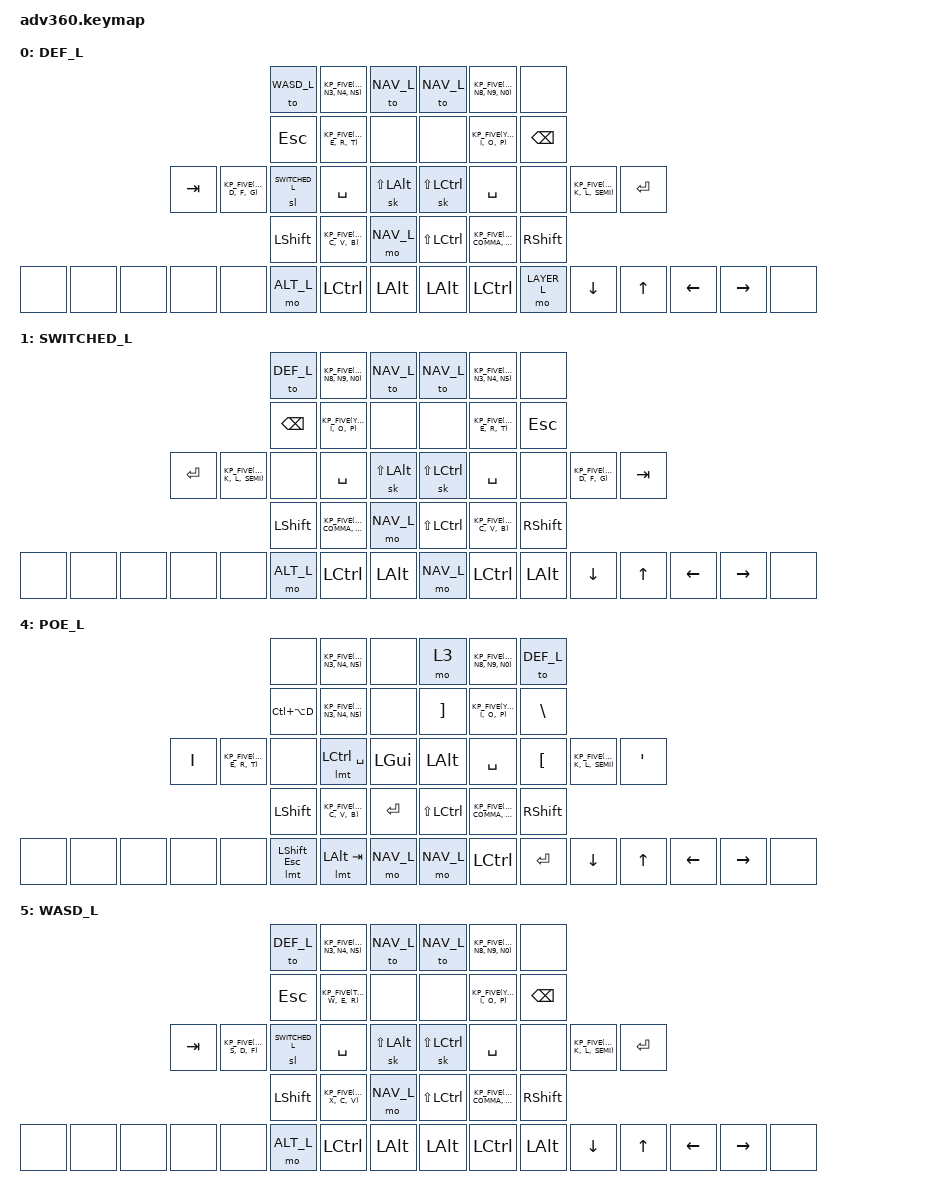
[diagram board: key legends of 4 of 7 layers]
#include <behaviors.dtsi>
#include <dt-bindings/zmk/keys.h>
#include <dt-bindings/zmk/bt.h>
#include <dt-bindings/zmk/rgb.h>
#include <dt-bindings/zmk/backlight.h>

#define TAPPING_TERM 210
#define SHIFT_TAP    170
#define QUICK_TAP    105

#define DEF_L      0
#define SWITCHED_L 1
#define NAV_L      2
#define ALT_L      3
#define POE_L      4
#define WASD_L     5
#define LAYER_L    6 

#define HRML(k1,k2,k3,k4) &lmt LCTRL k1  &lmt LALT k2  &lmt LGUI k3  &lst LSHFT k4
#define HRMR(k1,k2,k3,k4) &rst RSHFT k1  &rmt RGUI k2  &rmt RALT k3  &rmt RCTRL k4
#define KP_FIVE(k1,k2,k3,k4,k5) &kp k1  &kp k2  &kp k3  &kp k4  &kp k5

#define L_SHIFT 46
#define R_SHIFT 59
#define L_KEYS /*1*/0 1 2 3 4 5 6 /*2*/14 15 16 17 18 19 20 /*3*/28 29 30 31 32 33 34 35 36 /*4*/46 47 48 49 50 51 52 /*5*/60 61 62 63 64 65 66 67
#define R_KEYS /*1*/7 8 9 10 11 12 13 /*2*/21 22 23 24 25 26 27 /*3*/37 38 39 40 41 42 43 44 45 /*4*/53 54 55 56 57 58 59 /*6*/68 69 70 71 72 73 74 75

#define HOLD_TAP(name, tap_flavor, tap_term, ...) \
    name: name##_hold_tap {                       \
        label           = #name;                  \
        flavor          = #tap_flavor;            \
        compatible      = "zmk,behavior-hold-tap";\
        tapping-term-ms = <tap_term>;             \
        quick-tap-ms    = <QUICK_TAP>;            \
        #binding-cells  = <2>;                    \
        bindings        = <&kp>, <&kp>;           \
        __VA_ARGS__                               \
    };

#define LAYER_TAP(name, tap_flavor, tap_term, ...)\
    name: name##_layer_tap {                       \
        label           = #name;                  \
        flavor          = #tap_flavor;            \
        compatible      = "zmk,behavior-hold-tap";\
        tapping-term-ms = <tap_term>;             \
        quick-tap-ms    = <QUICK_TAP>;            \
        #binding-cells  = <2>;                    \
        bindings        = <&mo>, <&kp>;           \
        __VA_ARGS__                               \
    };

#define SEQUENCE_MACRO(name, keys)         \
    name: name##_macro {                   \
        label = #name;                     \
        compatible = "zmk,behavior-macro"; \
        wait-ms = <1>;                     \
        tap-ms = <1>;                      \
        #binding-cells = <0>;              \
        bindings = <keys>;                 \
    };

&sk {
    release-after-ms = <2000>;
    quick-release;
};

&mt {
  retro-tap;
};


/ {

  behaviors {
    #include "macros.dtsi"
    // Positional hold-tap for non-Shift modifiers
    HOLD_TAP(lmt, tap-preferred, TAPPING_TERM, hold-trigger-key-positions = <L_SHIFT R_KEYS>;)
    HOLD_TAP(rmt, tap-preferred, TAPPING_TERM, hold-trigger-key-positions = <R_SHIFT L_KEYS>;)
    // Positional hold-tap for Shift
    HOLD_TAP(lst, balanced, SHIFT_TAP, hold-trigger-key-positions = <R_KEYS>;)
    HOLD_TAP(rst, balanced, SHIFT_TAP, hold-trigger-key-positions = <L_KEYS>;)
    // Positional layer-tap
    LAYER_TAP(llt, tap-preferred, TAPPING_TERM, hold-trigger-key-positions = <L_SHIFT R_KEYS>;)
    LAYER_TAP(rlt, tap-preferred, TAPPING_TERM, hold-trigger-key-positions = <R_SHIFT L_KEYS>;)
  };

  macros {
    SEQUENCE_MACRO(terminal_next, &kp LS(LC(T)) &kp LS(LC(J)))
    SEQUENCE_MACRO(terminal_prev, &kp LS(LC(T)) &kp LS(LC(K)))
  };

  keymap {
    compatible = "zmk,keymap";

    DEF_L {
      bindings = <
        &to WASD_L KP_FIVE(N1, N2, N3, N4, N5)    &to NAV_L                                                                                         &to NAV_L     KP_FIVE(N6, N7, N8, N9, N0)                       &none
        &kp ESC    KP_FIVE(Q,  W,  E,  R,  T)     &none                                                                                             &none         KP_FIVE(Y,  U,  I,  O,  P)                        &kp BSPC
        &kp TAB    KP_FIVE(A,  S,  D,  F,  G)     &sl SWITCHED_L                      &kp SPACE &sk LS(LALT)  &sk LS(LCTRL)  &kp SPACE              &none         KP_FIVE(H,  J,  K,  L,  SEMI)                     &kp ENTER
        &kp LSHFT  KP_FIVE(Z,  X,  C,  V,  B)                                                      &mo NAV_L  &kp LS(LCTRL)                                       KP_FIVE(N,  M, COMMA, DOT, FSLH)                  &kp RSHFT
        &none &none &none &none &none                                         &mo ALT_L  &kp LCTRL  &kp LALT  &kp LALT &kp LCTRL &mo LAYER_L                            &kp DOWN &kp UP  &kp LEFT &kp RIGHT  &none
      >;
    };
    SWITCHED_L {
      bindings = <
        &to DEF_L  KP_FIVE(N6, N7, N8, N9, N0)    &to NAV_L                                                                                         &to NAV_L     KP_FIVE(N1, N2, N3, N4, N5)                       &none
        &kp BSPC   KP_FIVE(Y,  U,  I,  O,  P)     &none                                                                                             &none         KP_FIVE(Q,  W,  E,  R,  T)                        &kp ESC
        &kp ENTER  KP_FIVE(H,  J,  K,  L,  SEMI)  &none                               &kp SPACE &sk LS(LALT)  &sk LS(LCTRL)  &kp SPACE              &none         KP_FIVE(A,  S,  D,  F,  G)                     &kp TAB
        &kp LSHFT  KP_FIVE(N,  M, COMMA, DOT, FSLH)                                                &mo NAV_L  &kp LS(LCTRL)                                       KP_FIVE(Z,  X,  C,  V,  B)                  &kp RSHFT
        &none &none &none &none &none                                         &mo ALT_L  &kp LCTRL  &kp LALT  &mo NAV_L &kp LCTRL &kp LEFT_ALT                                &kp DOWN &kp UP  &kp LEFT &kp RIGHT  &none
      >;
    };
    NAV_L {
      bindings = <
        &trans &trans &trans &trans &trans &trans  &bootloader                                                  &bootloader &trans &trans &trans &trans  &trans  &trans
        &trans &kp LA(F4) &trans &trans &trans &trans  &trans                                                   &trans &kp LS(LC(TAB)) &kp LA(ESC) &kp LS(LA(ESC)) &kp LC(TAB)  &trans  &trans
        &trans &trans &trans &trans &trans &trans  &kp GRAVE        &trans &trans &trans &trans                 &trans &kp LEFT &kp DOWN &kp UP &kp RIGHT  &trans  &trans
        &trans &trans &trans &trans &trans &trans                      &trans &trans                            &trans &terminal_next &terminal_prev &trans &trans  &trans
        &trans &trans &trans &trans &trans               &trans &trans &trans &trans &trans &trans              &trans &trans &trans  &trans  &trans
      >;
    };
    ALT_L {
      bindings = <
        &none &none          &none          &none       &none          &none       &none                                                                               &none  &none         &none         &none         &none         &none       &none
        &none &kp LS(N1)     &kp LS(N2)     &kp LS(N3)  &kp LS(N4)     &kp LS(N5)  &none                                                                               &none  &kp LS(N6)    &kp LS(N7)    &kp LS(N8)    &kp LS(N9)    &kp LS(N0)  &none
        &none &kp MINUS      &kp EQUAL      &kp BSPC    &kp GRAVE      &none       &none                       &none  &none  &none  &none                              &none  &none         &kp LBKT      &kp RBKT      &kp BSLH      &kp SQT     &none
        &none &kp LS(MINUS)  &kp LS(EQUAL)  &none       &kp LS(GRAVE)  &none                                          &none  &none                                     &none  &kp LS(LBKT)  &kp LS(RBKT)  &kp LS(BSLH)  &kp LS(SQT)   &none       
        &none &none          &none          &none       &none                                           &none  &none  &none  &none  &none  &none                       &none  &none         &none         &none         &none
      >;
    };
    POE_L {
      bindings = <
        &none          KP_FIVE(N1, N2, N3, N4, N5)    &none                                                                                               &mo 3     KP_FIVE(N6, N7, N8, N9, N0)          &to DEF_L
        &kp LC(LA(D))  KP_FIVE(N1, N2, N3, N4, N5)    &none                                                                                               &kp RBKT  KP_FIVE(Y,  U,  I,  O,  P)           &kp BSLH
        &kp I          KP_FIVE(Q,  W,  E,  R,  T)     &none                            &lmt LCTRL SPACE &kp LGUI  &kp LALT  &kp SPACE                     &kp LBKT  KP_FIVE(H,  J,  K,  L,  SEMI)        &kp SQT
        &kp LSHFT      KP_FIVE(Z,  X,  C,  V,  B)                                                      &kp ENTER  &kp LS(LCTRL)                                      KP_FIVE(N,  M, COMMA, DOT, FSLH)     &kp RSHFT
        &none &none &none &none &none                                    &lmt LSHFT ESC &lmt LALT TAB  &mo NAV_L  &mo NAV_L &kp LCTRL &kp ENTER                                 &kp DOWN &kp UP  &kp LEFT &kp RIGHT  &none
      >;
    };
    WASD_L {
      bindings = <
        &to DEF_L  KP_FIVE(N1, N2, N3, N4, N5)    &to NAV_L                                                                                         &to NAV_L     KP_FIVE(N6, N7, N8, N9, N0)                       &none
        &kp ESC    KP_FIVE(T,  Q,  W,  E,  R)     &none                                                                                             &none         KP_FIVE(Y,  U,  I,  O,  P)                        &kp BSPC
        &kp TAB    KP_FIVE(G,  A,  S,  D,  F)     &sl SWITCHED_L                      &kp SPACE &sk LS(LALT)  &sk LS(LCTRL)  &kp SPACE              &none         KP_FIVE(H,  J,  K,  L,  SEMI)                     &kp ENTER
        &kp LSHFT  KP_FIVE(B,  Z,  X,  C,  V)                                                      &mo NAV_L  &kp LS(LCTRL)                                       KP_FIVE(N,  M, COMMA, DOT, FSLH)                  &kp RSHFT
        &none &none &none &none &none                                         &mo ALT_L  &kp LCTRL  &kp LALT  &kp LALT &kp LCTRL &kp LEFT_ALT                            &kp DOWN &kp UP  &kp LEFT &kp RIGHT  &none
      >;
    };
    LAYER_L {
      bindings = <
        &trans &trans &trans &trans &trans &trans  &trans                                                        &trans &trans &trans &trans &trans  &trans  &trans
        &trans &trans &trans &trans &trans &trans  &trans                                                        &trans &trans &trans &trans &trans  &trans  &trans
        &trans &trans &trans &trans &trans &trans  &trans               &trans &trans &trans &trans              &trans &trans &trans &trans &trans  &trans  &trans
        &trans &trans &trans &trans &trans &trans                              &trans &trans                     &trans &trans &trans &trans &trans  &trans
        &trans &trans &trans &trans &trans                       &trans &trans &trans &trans &trans &trans        &trans &trans &trans &trans &trans
      >;
    };
    // fn {
    //   bindings = <
    //     &trans &trans &trans &trans &trans &trans  &trans                                                        &trans &trans &trans &trans &trans  &trans  &trans
    //     &trans &trans &trans &trans &trans &trans  &trans                                                        &trans &trans &trans &trans &trans  &trans  &trans
    //     &trans &trans &trans &trans &trans &trans  &trans               &trans &trans &trans &trans              &trans &trans &trans &trans &trans  &trans  &trans
    //     &trans &trans &trans &trans &trans &trans                              &trans &trans                     &trans &trans &trans &trans &trans  &trans
    //     &trans &trans &trans &trans &trans                       &trans &trans &trans &trans &trans &trans        &trans &trans &trans &trans &trans
    //   >;
    // };
  };
};
